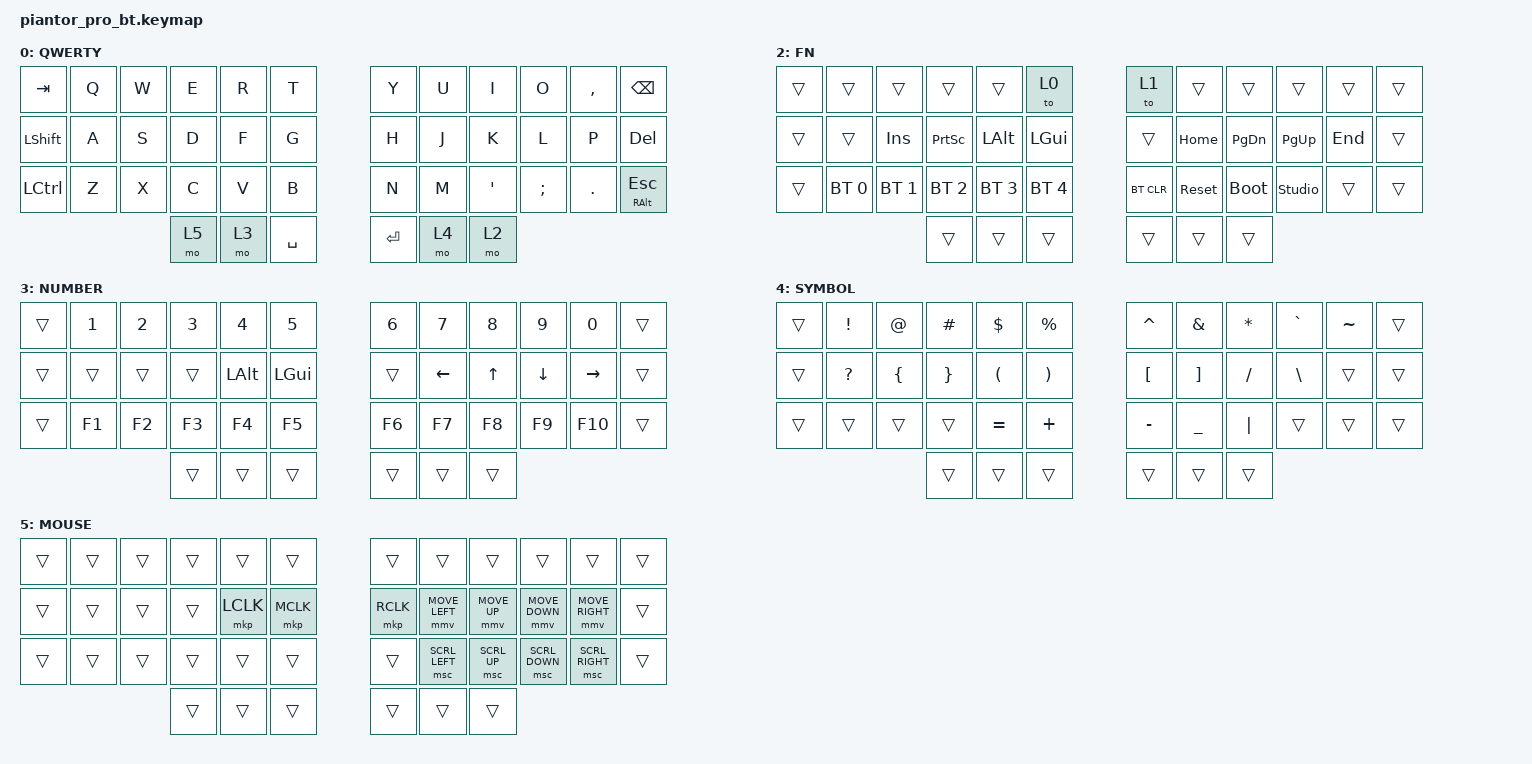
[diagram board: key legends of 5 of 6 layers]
/*
 * Copyright (c) 2020 The ZMK Contributors
 *
 * SPDX-License-Identifier: MIT
 */

#include <behaviors.dtsi>
#include <dt-bindings/zmk/keys.h>
#include <dt-bindings/zmk/bt.h>
#include <dt-bindings/zmk/rgb.h>

#define ZMK_POINTING_DEFAULT_MOVE_VAL 600  // default: 600
#define ZMK_POINTING_DEFAULT_SCRL_VAL 10   // default: 10

#include <dt-bindings/zmk/pointing.h>

#define COMBO(NAME, BINDINGS, KEYPOS) \
  combo_##NAME { \
    timeout-ms = <50>; \
    bindings = <BINDINGS>; \
    key-positions = <KEYPOS>; \
    layers = <0>; \
  };

/ {
    chosen {
        zmk,physical-layout = &default_layout;
    };
};


/ {
    keymap {
        compatible = "zmk,keymap";

        layer_0 {
            // --------------------------------------------------------------------------------
            // |  TAB  |  Q  |  W  |  E  |  R  |  T  |  Y  |  U   |  I  |  O  |  ,  | BSPC     |
            // | LSHFT |  A  |  S  |  D  |  F  |  G  |  H  |  J   |  K  |  L  |  P  | DEL      |
            // | LCTRL |  Z  |  X  |  C  |  V  |  B  |  N  |  M   |  '  |  ;  |  .  | RALT/ESC |
            //                     | MOUSE | NUM |SPACE| RET | SYM  | FN  |
            display-name = "QWERTY";
            bindings = <
                &kp TAB    &kp Q &kp W &kp E  &kp R  &kp T  &kp Y  &kp U  &kp I   &kp O    &kp COMMA &kp BSPC
                &kp LSHFT  &kp A &kp S &kp D  &kp F  &kp G  &kp H  &kp J  &kp K   &kp L    &kp P     &kp DEL
                &kp LCTRL  &kp Z &kp X &kp C  &kp V  &kp B  &kp N  &kp M  &kp SQT &kp SEMI &kp DOT   &mt RALT ESC
                                       &mo 5  &mo 3 &kp SPACE &kp RET &mo 4 &mo 2
            >;
        };

        layer_1 {
            // -------------------------------------------------------------------------------------------------
            // |      |       |       |       |       |       |       |       |       |      |       |      |
            // |      |       |       |       |       |       |       |       |       |      |       |      |
            // |      |       |       |       |       |       |       |       |       |      |       |      |
            //                        |       |       |       |       |       |       |
            display-name = "Empty";
            bindings = <
                &trans &trans &trans &trans &trans &trans &trans &trans &trans &trans &trans &trans
                &trans &trans &trans &trans &trans &trans &trans &trans &trans &trans &trans &trans
                &trans &trans &trans &trans &trans &trans &trans &trans &trans &trans &trans &trans
                                     &trans &trans &trans &trans &trans
            >;
        };

        layer_2 {
            // -----------------------------------------------------------------------------------------
            // |      |         |        |      |       | TO0     | TO1    |      |       |        |     |     |
            // |      |         |  INS   | PRNT | LALT  | LGUI    |        | POS1 | PG_DN | PG_UP  | END |     |
            // |      |  BT0    |  BT2   | BT3  |  BT4  | BT5     |  BTCR  | RST  | BOOT  | Unlock |     |     |
            //                           |      |       |         |        |      |       |
            display-name = "FN";
            bindings = <
                &trans &trans       &trans        &trans          &trans       &to 0        &to 1      &trans     &trans      &trans         &trans  &trans
                &trans &trans       &kp INS       &kp PRINTSCREEN &kp LALT     &kp LGUI     &trans     &kp HOME   &kp PG_DN   &kp PG_UP      &kp END &trans
                &trans &bt BT_SEL 0 &bt BT_SEL 1  &bt BT_SEL 2    &bt BT_SEL 3 &bt BT_SEL 4 &bt BT_CLR &sys_reset &bootloader &studio_unlock &trans  &trans
                                                  &trans          &trans       &trans       &trans     &trans     &trans
            >;
        };

        layer_3 {
            // -----------------------------------------------------------------------------------------
            // |      |  1  |  2  |  3  |  4    |  5   |  6  |  7  |  8  |  9  |  0  |      |
            // |      |     |     |     | LALT  | LGUI |     | LFT | UP  | DWN | RGT |      |
            // |      | F1  | F2  | F3  | F4    | F5   | F6  | F7  | F8  | F9  | F10 |      |
            //                    |     |       |      |     |     |     |
            display-name = "NUMBER";
            bindings = <
                &trans  &kp N1   &kp N2  &kp N3 &kp N4   &kp N5   &kp N6 &kp N7   &kp N8   &kp N9   &kp N0    &trans
                &trans  &trans   &trans  &trans &kp LALT &kp LGUI &trans &kp LEFT &kp UP   &kp DOWN &kp RIGHT &trans
                &trans  &kp F1   &kp F2  &kp F3 &kp F4   &kp F5   &kp F6 &kp F7   &kp F8   &kp F9   &kp F10   &trans
                                         &trans &trans   &trans   &trans &trans   &trans
            >;
        };

        layer_4 {
            // -----------------------------------------------------------------------------------------
            // |      |  !  |  @  |  #  |  $   |  %   |  ^  |  &  |  *  |  `  |  ~  |     |
            // |      |  ?  |  {  |  }  |  (   |  )   |  [  |  ]  |  /  |  \  |     |     |
            // |      |     |     |     |  =   |  +   |  -  |  _  | "|" |     |     |     |
            //                    |     |      |      |     |     |     |
            display-name = "SYMBOL";
            bindings = <
                &trans  &kp EXCL  &kp AT     &kp HASH &kp DLLR  &kp PRCNT  &kp CARET &kp AMPS   &kp ASTRK &kp GRAVE &kp TILDE &trans
                &trans  &kp QMARK &kp LBRC   &kp RBRC &kp LPAR  &kp RPAR   &kp LBKT  &kp RBKT   &kp FSLH  &kp BSLH  &trans    &trans
                &trans  &trans    &trans     &trans   &kp EQUAL &kp PLUS   &kp MINUS &kp UNDER  &kp PIPE  &trans    &trans    &trans
                                            &trans   &trans    &trans     &trans  &trans   &trans
            >;
        };

        layer_5 {
            // -----------------------------------------------------------------------------------------
            // |      |      |      |      |      |      |      |      |      |      |      |      |
            // |      |      |      |      | LCLK | MCLK | RCLK | ←    | ↑    | ↓    | →    |      |
            // |      |      |      |      |      |      |      | ⇤ SCR| ⇡ SCR| ⇣ SCR| ⇥ SCR|      |
            //                      |      |      |      |      |      |      |
            display-name = "MOUSE";
            bindings = <
                &trans   &trans   &trans   &trans   &trans    &trans    &trans    &trans          &trans         &trans          &trans           &trans
                &trans   &trans   &trans   &trans   &mkp LCLK &mkp MCLK &mkp RCLK &mmv MOVE_LEFT  &mmv MOVE_UP   &mmv MOVE_DOWN  &mmv MOVE_RIGHT  &trans
                &trans   &trans   &trans   &trans   &trans    &trans    &trans    &msc SCRL_LEFT  &msc SCRL_UP   &msc SCRL_DOWN  &msc SCRL_RIGHT  &trans
                                           &trans   &trans    &trans    &trans    &trans          &trans
            >;
        };

    };
};


// TRANS
//        layer_0 {
//            // -------------------------------------------------------------------------------------------------
//            // |      |       |       |       |       |       |       |       |       |      |       |      |
//            // |      |       |       |       |       |       |       |       |       |      |       |      |
//            // |      |       |       |       |       |       |       |       |       |      |       |      |
//            //                        |       |       |       |       |       |       |
//            display-name = "FN";
//            bindings = <
//                &trans &trans &trans &trans &trans &trans &trans &trans &trans &trans &trans &trans
//                &trans &trans &trans &trans &trans &trans &trans &trans &trans &trans &trans &trans
//                &trans &trans &trans &trans &trans &trans &trans &trans &trans &trans &trans &trans
//                                     &trans &trans &trans &trans &trans
//            >;
//        };


// GALLIUM
//        layer_0 {
//            // -----------------------------------------------------------------------------------------
//            // |  TAB  |  B  |  L  |  D  |  C  |  V  |  J  |  Y  |  O  |  U  |  ,  | BSPC     |
//            // | LSHFT |  N  |  R  |  T  |  S  |  G  |  P  |  H  |  A  |  E  |  I  | DEL      |
//            // | LCTRL |  X  |  Q  |  M  |  W  |  Z  |  K  |  F  |  '  |  ;  |  .  | RALT/ESC |
//            //                     | GAL | NUM |SPACE| RET | SYM | FN  |
//            display-name = "GALLIUM";
//            bindings = <
//                &kp TAB   &kp B &kp L &kp D &kp C &kp V     &kp J   &kp Y &kp O   &kp U    &kp COMMA &kp BSPC
//                &kp LSHFT &kp N &kp R &kp T &kp S &kp G     &kp P   &kp H &kp A   &kp E    &kp I     &kp DEL
//                &kp LCTRL &kp X &kp Q &kp M &kp W &kp Z     &kp K   &kp F &kp SQT &kp SEMI &kp DOT   &mt RALT ESC
//                                      &mo 5 &mo 3 &kp SPACE &kp RET &mo 4 &mo 2
//            >;
//        };

